# CY8C5888LTI_LP097 register map
File version: 0.1
CY8C58LP
Registers are 8-bit, read-write, no defined reset value unless marked. A register's access mark holds for its fields unless they carry their own. Offsets are from the block's base; lines under a group give offsets from that group; [hi:lo] are bit positions; {n}, {i} and the like mark numbered series; 'fields as' and 'values as' point back to an identical list; <NAME> marks a mode.

## Memory map
0x00000000 I2Sfive
0x00000000 I2Sseven
0x00000000 I2Ssix
0x00000000 I2Seight
0x00000000 I2Sthree
0x00000000 I2Stwo
0x00000000 I2Sfour
0x00000000 I2Sone

## I2Sfive
Base 0x00000000
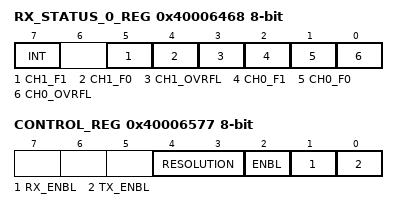
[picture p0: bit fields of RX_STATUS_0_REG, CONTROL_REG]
0x40006468 RX_STATUS_0_REG
  [7] INT ro — Interrupt bit
  [5] CH1_F1 ro — Stereo channel 1 FIFO 1 state
    0=EMPTY; 1=NOT_EMPTY
  [4] CH1_F0 ro — Stereo channel 1 FIFO 0 state
    0=EMPTY; 1=NOT_EMPTY
  [3] CH1_OVRFL ro — Stereo channel 1 FIFO overflow
    0=NO_OVERFLOW; 1=OVERFLOW
  [2] CH0_F1 ro — Stereo channel 0 FIFO 1 state
    0=EMPTY; 1=NOT_EMPTY
  [1] CH0_F0 ro — Stereo channel 0 FIFO 0 state
    0=EMPTY; 1=NOT_EMPTY
  [0] CH0_OVRFL ro — Stereo channel 0 FIFO overflow
    0=NO_OVERFLOW; 1=OVERFLOW
0x40006577 CONTROL_REG
  [4:3] RESOLUTION — Specifies data bits value. Applicable only if dynamic bit resolution is selected.
    0=Cy8_BIT; 1=Cy16_BIT; 2=Cy24_BIT; 3=Cy32_BIT
  [2] ENBL — Starts the generation of the WS and SCK outputs.
    1=ENABLED; 0=DISABLED
  [1] RX_ENBL — Enables Rx direction. Applicable only if Rx direction presents for the component.
    1=ENABLED; 0=DISABLED
  [0] TX_ENBL — Enables Tx direction. Applicable only if Tx direction presents for the component.
    1=ENABLED; 0=DISABLED

## I2Sseven
Base 0x00000000
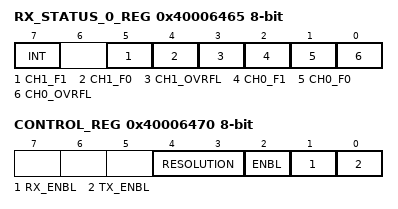
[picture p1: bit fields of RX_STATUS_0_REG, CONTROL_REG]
0x40006465 RX_STATUS_0_REG
  [7] INT ro — Interrupt bit
  [5] CH1_F1 ro — Stereo channel 1 FIFO 1 state
    0=EMPTY; 1=NOT_EMPTY
  [4] CH1_F0 ro — Stereo channel 1 FIFO 0 state
    0=EMPTY; 1=NOT_EMPTY
  [3] CH1_OVRFL ro — Stereo channel 1 FIFO overflow
    0=NO_OVERFLOW; 1=OVERFLOW
  [2] CH0_F1 ro — Stereo channel 0 FIFO 1 state
    0=EMPTY; 1=NOT_EMPTY
  [1] CH0_F0 ro — Stereo channel 0 FIFO 0 state
    0=EMPTY; 1=NOT_EMPTY
  [0] CH0_OVRFL ro — Stereo channel 0 FIFO overflow
    0=NO_OVERFLOW; 1=OVERFLOW
0x40006470 CONTROL_REG
  [4:3] RESOLUTION — Specifies data bits value. Applicable only if dynamic bit resolution is selected.
    0=Cy8_BIT; 1=Cy16_BIT; 2=Cy24_BIT; 3=Cy32_BIT
  [2] ENBL — Starts the generation of the WS and SCK outputs.
    1=ENABLED; 0=DISABLED
  [1] RX_ENBL — Enables Rx direction. Applicable only if Rx direction presents for the component.
    1=ENABLED; 0=DISABLED
  [0] TX_ENBL — Enables Tx direction. Applicable only if Tx direction presents for the component.
    1=ENABLED; 0=DISABLED

## I2Ssix
Base 0x00000000
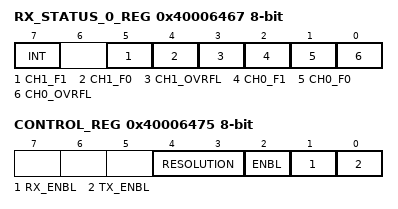
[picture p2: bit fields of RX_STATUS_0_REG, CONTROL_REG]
0x40006467 RX_STATUS_0_REG
  [7] INT ro — Interrupt bit
  [5] CH1_F1 ro — Stereo channel 1 FIFO 1 state
    0=EMPTY; 1=NOT_EMPTY
  [4] CH1_F0 ro — Stereo channel 1 FIFO 0 state
    0=EMPTY; 1=NOT_EMPTY
  [3] CH1_OVRFL ro — Stereo channel 1 FIFO overflow
    0=NO_OVERFLOW; 1=OVERFLOW
  [2] CH0_F1 ro — Stereo channel 0 FIFO 1 state
    0=EMPTY; 1=NOT_EMPTY
  [1] CH0_F0 ro — Stereo channel 0 FIFO 0 state
    0=EMPTY; 1=NOT_EMPTY
  [0] CH0_OVRFL ro — Stereo channel 0 FIFO overflow
    0=NO_OVERFLOW; 1=OVERFLOW
0x40006475 CONTROL_REG
  [4:3] RESOLUTION — Specifies data bits value. Applicable only if dynamic bit resolution is selected.
    0=Cy8_BIT; 1=Cy16_BIT; 2=Cy24_BIT; 3=Cy32_BIT
  [2] ENBL — Starts the generation of the WS and SCK outputs.
    1=ENABLED; 0=DISABLED
  [1] RX_ENBL — Enables Rx direction. Applicable only if Rx direction presents for the component.
    1=ENABLED; 0=DISABLED
  [0] TX_ENBL — Enables Tx direction. Applicable only if Tx direction presents for the component.
    1=ENABLED; 0=DISABLED

## I2Seight
Base 0x00000000
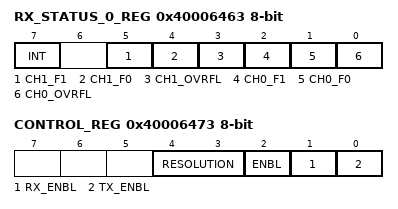
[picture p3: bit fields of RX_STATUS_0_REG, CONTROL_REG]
0x40006463 RX_STATUS_0_REG
  [7] INT ro — Interrupt bit
  [5] CH1_F1 ro — Stereo channel 1 FIFO 1 state
    0=EMPTY; 1=NOT_EMPTY
  [4] CH1_F0 ro — Stereo channel 1 FIFO 0 state
    0=EMPTY; 1=NOT_EMPTY
  [3] CH1_OVRFL ro — Stereo channel 1 FIFO overflow
    0=NO_OVERFLOW; 1=OVERFLOW
  [2] CH0_F1 ro — Stereo channel 0 FIFO 1 state
    0=EMPTY; 1=NOT_EMPTY
  [1] CH0_F0 ro — Stereo channel 0 FIFO 0 state
    0=EMPTY; 1=NOT_EMPTY
  [0] CH0_OVRFL ro — Stereo channel 0 FIFO overflow
    0=NO_OVERFLOW; 1=OVERFLOW
0x40006473 CONTROL_REG
  [4:3] RESOLUTION — Specifies data bits value. Applicable only if dynamic bit resolution is selected.
    0=Cy8_BIT; 1=Cy16_BIT; 2=Cy24_BIT; 3=Cy32_BIT
  [2] ENBL — Starts the generation of the WS and SCK outputs.
    1=ENABLED; 0=DISABLED
  [1] RX_ENBL — Enables Rx direction. Applicable only if Rx direction presents for the component.
    1=ENABLED; 0=DISABLED
  [0] TX_ENBL — Enables Tx direction. Applicable only if Tx direction presents for the component.
    1=ENABLED; 0=DISABLED
